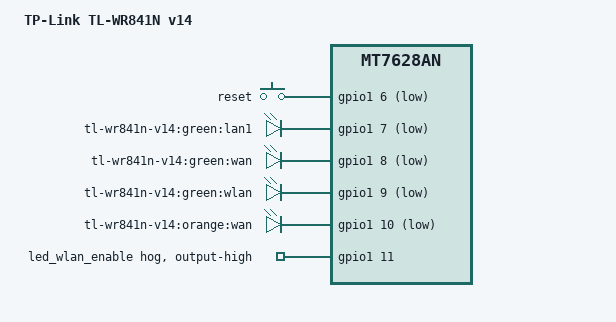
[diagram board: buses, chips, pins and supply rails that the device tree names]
/dts-v1/;

#include "TPLINK-4M.dtsi"

#include <dt-bindings/gpio/gpio.h>
#include <dt-bindings/input/input.h>

/ {
	compatible = "tplink,tl-wr841n-v14", "mediatek,mt7628an-soc";
	model = "TP-Link TL-WR841N v14";

	aliases {
		led-boot = &led_wlan;
		led-failsafe = &led_wlan;
		led-wlan = &led_wlan;
		led-upgrade = &led_wlan;
	};


	keys {
		compatible = "gpio-keys-polled";
		poll-interval = <20>;

		reset {
			label = "reset";
			gpios = <&gpio1 6 GPIO_ACTIVE_LOW>;
			linux,code = <KEY_RESTART>;
		};

	};

	leds {
		compatible = "gpio-leds";

		lan {
			label = "tl-wr841n-v14:green:lan1";
			gpios = <&gpio1 7 GPIO_ACTIVE_LOW>;
		};

		wan_green {
			label = "tl-wr841n-v14:green:wan";
			gpios = <&gpio1 8 GPIO_ACTIVE_LOW>;
		};

		led_wlan: wlan {
			label = "tl-wr841n-v14:green:wlan";
			gpios = <&gpio1 9 GPIO_ACTIVE_LOW>;
			linux,default-trigger = "phy0tpt";
		};
		wan_orange {
			label = "tl-wr841n-v14:orange:wan";
			gpios = <&gpio1 10 GPIO_ACTIVE_LOW>;
		};
	};
};

&pinctrl {
	state_default: pinctrl0 {
		gpio {
			ralink,group = "p4led_an", "p3led_an", "p2led_an", "p1led_an", "p0led_an", "wdt";
			ralink,function = "gpio";
		};
	};
};
&gpio1 {
	led_wlan_enable {
		gpio-hog;
		gpios = <11 GPIO_ACTIVE_HIGH>;
		output-high;
	};
};

&esw {
	mediatek,portmap = <0x3e>;
};
